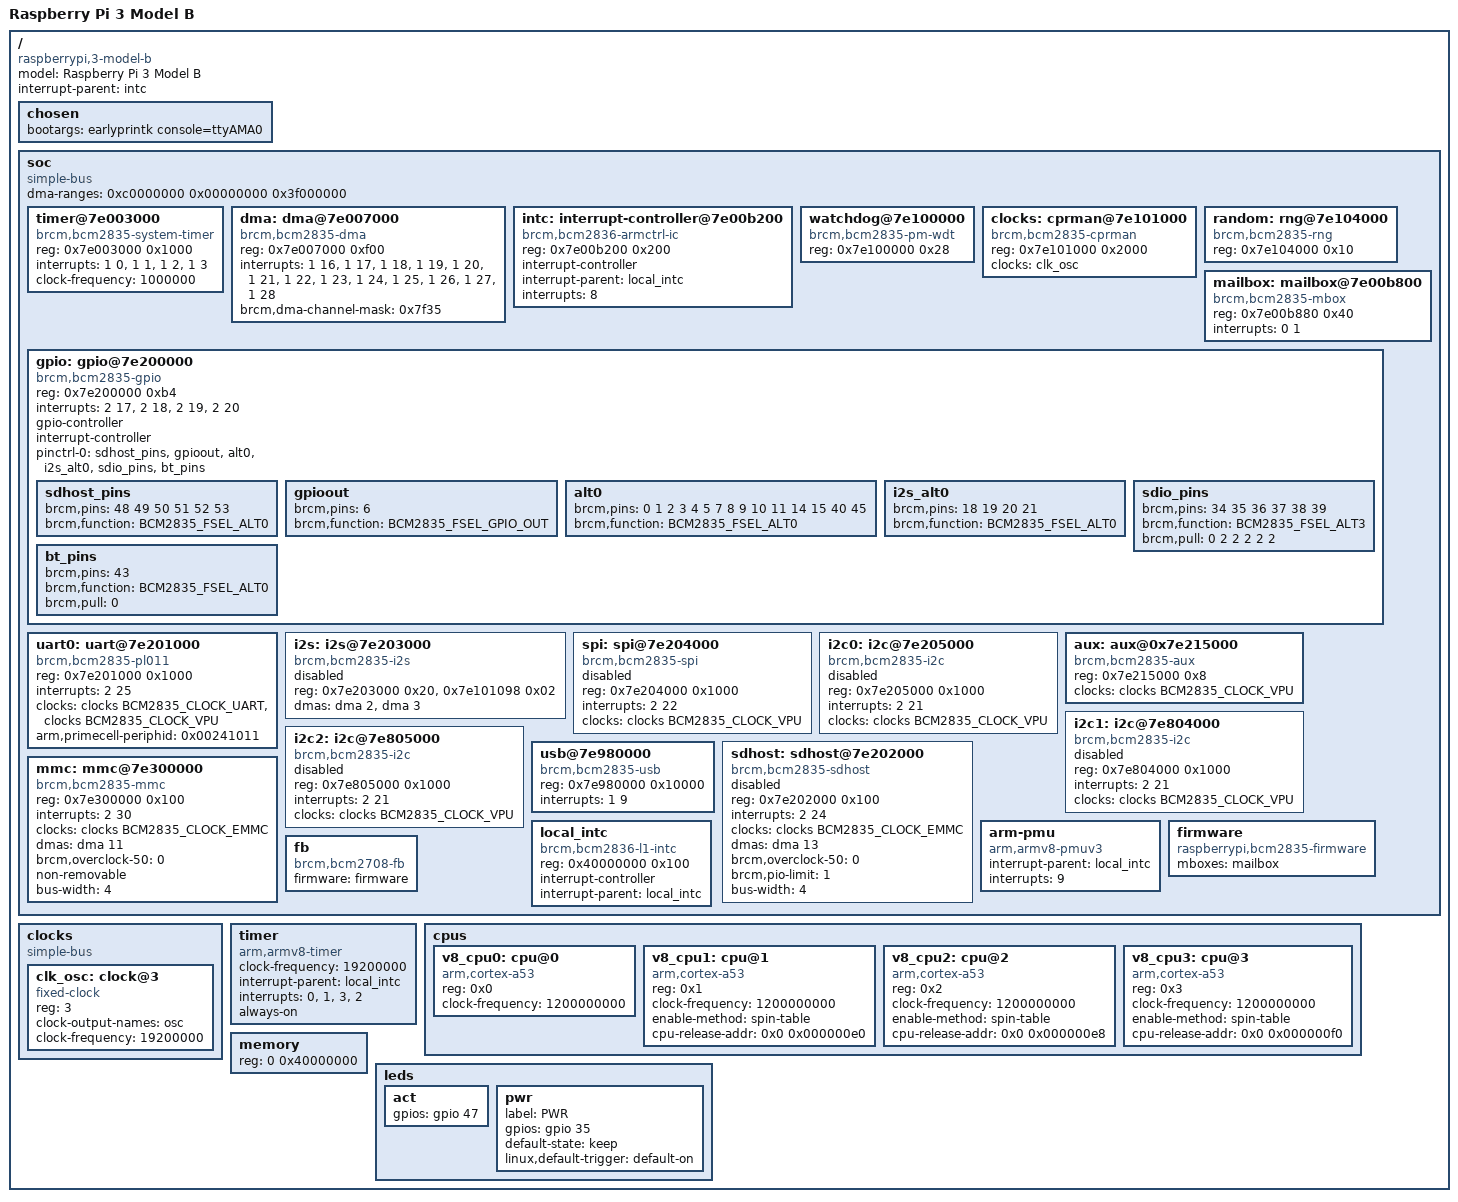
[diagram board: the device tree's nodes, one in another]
/dts-v1/;

/memreserve/ 0x00000000 0x00001000;

#include <dt-bindings/pinctrl/bcm2835.h>
#include <dt-bindings/clock/bcm2835.h>
#include "../../../../arm/boot/dts/skeleton.dtsi"

/ {
	compatible = "brcm,bcm2835";
	model = "BCM2835";
	interrupt-parent = <&intc>;

	chosen {
		bootargs = "earlyprintk console=ttyAMA0";
	};

	soc {
		compatible = "simple-bus";
		#address-cells = <1>;
		#size-cells = <1>;

		timer@7e003000 {
			compatible = "brcm,bcm2835-system-timer";
			reg = <0x7e003000 0x1000>;
			interrupts = <1 0>, <1 1>, <1 2>, <1 3>;
			/* This could be a reference to BCM2835_CLOCK_TIMER,
			 * but we don't have the driver using the common clock
			 * support yet.
			 */
			clock-frequency = <1000000>;
		};

		dma: dma@7e007000 {
			compatible = "brcm,bcm2835-dma";
			reg = <0x7e007000 0xf00>;
			interrupts = <1 16>,
				     <1 17>,
				     <1 18>,
				     <1 19>,
				     <1 20>,
				     <1 21>,
				     <1 22>,
				     <1 23>,
				     <1 24>,
				     <1 25>,
				     <1 26>,
				     <1 27>,
				     <1 28>;

			#dma-cells = <1>;
			brcm,dma-channel-mask = <0x7f35>;
		};

		intc: interrupt-controller@7e00b200 {
			compatible = "brcm,bcm2835-armctrl-ic";
			reg = <0x7e00b200 0x200>;
			interrupt-controller;
			#interrupt-cells = <2>;
		};

		watchdog@7e100000 {
			compatible = "brcm,bcm2835-pm-wdt";
			reg = <0x7e100000 0x28>;
		};

		clocks: cprman@7e101000 {
			compatible = "brcm,bcm2835-cprman";
			#clock-cells = <1>;
			reg = <0x7e101000 0x2000>;

			/* CPRMAN derives everything from the platform's
			 * oscillator.
			 */
			clocks = <&clk_osc>;
		};

		random: rng@7e104000 {
			compatible = "brcm,bcm2835-rng";
			reg = <0x7e104000 0x10>;
		};

		mailbox: mailbox@7e00b800 {
			compatible = "brcm,bcm2835-mbox";
			reg = <0x7e00b880 0x40>;
			interrupts = <0 1>;
			#mbox-cells = <0>;
		};

		gpio: gpio@7e200000 {
			compatible = "brcm,bcm2835-gpio";
			reg = <0x7e200000 0xb4>;
			/*
			 * The GPIO IP block is designed for 3 banks of GPIOs.
			 * Each bank has a GPIO interrupt for itself.
			 * There is an overall "any bank" interrupt.
			 * In order, these are GIC interrupts 17, 18, 19, 20.
			 * Since the BCM2835 only has 2 banks, the 2nd bank
			 * interrupt output appears to be mirrored onto the
			 * 3rd bank's interrupt signal.
			 * So, a bank0 interrupt shows up on 17, 20, and
			 * a bank1 interrupt shows up on 18, 19, 20!
			 */
			interrupts = <2 17>, <2 18>, <2 19>, <2 20>;

			gpio-controller;
			#gpio-cells = <2>;

			interrupt-controller;
			#interrupt-cells = <2>;
		};

		uart0: uart@7e201000 {
			compatible = "brcm,bcm2835-pl011", "arm,pl011", "arm,primecell";
			reg = <0x7e201000 0x1000>;
			interrupts = <2 25>;
			clocks = <&clocks BCM2835_CLOCK_UART>,
				 <&clocks BCM2835_CLOCK_VPU>;
			clock-names = "uartclk", "apb_pclk";
			arm,primecell-periphid = <0x00241011>;
		};

		i2s: i2s@7e203000 {
			compatible = "brcm,bcm2835-i2s";
			reg = <0x7e203000 0x20>,
			      <0x7e101098 0x02>;

			dmas = <&dma 2>,
			       <&dma 3>;
			dma-names = "tx", "rx";
			status = "disabled";
		};

		spi: spi@7e204000 {
			compatible = "brcm,bcm2835-spi";
			reg = <0x7e204000 0x1000>;
			interrupts = <2 22>;
			clocks = <&clocks BCM2835_CLOCK_VPU>;
			#address-cells = <1>;
			#size-cells = <0>;
			status = "disabled";
		};

		i2c0: i2c@7e205000 {
			compatible = "brcm,bcm2835-i2c";
			reg = <0x7e205000 0x1000>;
			interrupts = <2 21>;
			clocks = <&clocks BCM2835_CLOCK_VPU>;
			#address-cells = <1>;
			#size-cells = <0>;
			status = "disabled";
		};

		aux: aux@0x7e215000 {
			compatible = "brcm,bcm2835-aux";
			#clock-cells = <1>;
			reg = <0x7e215000 0x8>;
			clocks = <&clocks BCM2835_CLOCK_VPU>;
		};

#if 0
		sdhci: sdhci@7e300000 {
			compatible = "brcm,bcm2835-sdhci";
			reg = <0x7e300000 0x100>;
			interrupts = <2 30>;
			clocks = <&clocks BCM2835_CLOCK_EMMC>;
                        overclock_50 = <0>;
                        force_pio = <0>;
                        pio_limit = <0>;
                        debug = <0>;
			bus-width = <4>;
		};
#endif

		i2c1: i2c@7e804000 {
			compatible = "brcm,bcm2835-i2c";
			reg = <0x7e804000 0x1000>;
			interrupts = <2 21>;
			clocks = <&clocks BCM2835_CLOCK_VPU>;
			#address-cells = <1>;
			#size-cells = <0>;
			status = "disabled";
		};

		i2c2: i2c@7e805000 {
			compatible = "brcm,bcm2835-i2c";
			reg = <0x7e805000 0x1000>;
			interrupts = <2 21>;
			clocks = <&clocks BCM2835_CLOCK_VPU>;
			#address-cells = <1>;
			#size-cells = <0>;
			status = "disabled";
		};

		usb@7e980000 {
			compatible = "brcm,bcm2835-usb";
			reg = <0x7e980000 0x10000>;
			interrupts = <1 9>;
		};

		sdhost: sdhost@7e202000 {
			compatible = "brcm,bcm2835-sdhost";
			reg = <0x7e202000 0x100>;
			interrupts = <2 24>;
			clocks = <&clocks BCM2835_CLOCK_EMMC>;
			dmas = <&dma 13>;
			dma-names = "rx-tx";
			brcm,overclock-50 = <0>;
			brcm,pio-limit = <1>;
			status = "disabled";
		};

		mmc: mmc@7e300000 {
			compatible = "brcm,bcm2835-mmc";
			reg = <0x7e300000 0x100>;
			interrupts = <2 30>;
			clocks = <&clocks BCM2835_CLOCK_EMMC>;
			dmas = <&dma 11>;
			dma-names = "rx-tx";
			brcm,overclock-50 = <0>;
			status = "disabled";
		};

	};

	clocks {
		compatible = "simple-bus";
		#address-cells = <1>;
		#size-cells = <0>;


		/* The oscillator is the root of the clock tree. */
		clk_osc: clock@3 {
			compatible = "fixed-clock";
			reg = <3>;
			#clock-cells = <0>;
			clock-output-names = "osc";
			clock-frequency = <19200000>;
		};

	};
};

/ {
	compatible = "brcm,bcm2837";

	soc {
		ranges = <0x7e000000 0x3f000000 0x1000000>,
			 <0x40000000 0x40000000 0x00001000>;
		dma-ranges = <0xc0000000 0x00000000 0x3f000000>;

		local_intc: local_intc {
			compatible = "brcm,bcm2836-l1-intc";
			reg = <0x40000000 0x100>;
			interrupt-controller;
			#interrupt-cells = <1>;
			interrupt-parent = <&local_intc>;
		};

		arm-pmu {
			compatible = "arm,armv8-pmuv3";
			interrupt-parent = <&local_intc>;
			interrupts = <9>;
		};

		firmware: firmware {
			compatible = "raspberrypi,bcm2835-firmware";
			mboxes = <&mailbox>;
		};

		fb: fb {
			compatible = "brcm,bcm2708-fb";
			firmware = <&firmware>;
			status = "okay";
		};

	};

	timer {
		compatible = "arm,armv8-timer";
		clock-frequency = <19200000>;
		interrupt-parent = <&local_intc>;
		interrupts = <0>, // PHYS_SECURE_PPI
			     <1>, // PHYS_NONSECURE_PPI
			     <3>, // VIRT_PPI
			     <2>; // HYP_PPI
		always-on;
	};


	cpus: cpus {
		#address-cells = <1>;
		#size-cells = <0>;

		v8_cpu0: cpu@0 {
			device_type = "cpu";
			compatible = "arm,cortex-a53", "arm,armv8";
			reg = <0x0>;
			clock-frequency = <1200000000>;
		};

		v8_cpu1: cpu@1 {
			device_type = "cpu";
			compatible = "arm,cortex-a53", "arm,armv8";
			reg = <0x1>;
			clock-frequency = <1200000000>;
			enable-method = "spin-table";
			cpu-release-addr = <0x0 0x000000e0>;
		};

		v8_cpu2: cpu@2 {
			device_type = "cpu";
			compatible = "arm,cortex-a53", "arm,armv8";
			reg = <0x2>;
			clock-frequency = <1200000000>;
                        enable-method = "spin-table";
			cpu-release-addr = <0x0 0x000000e8>;
		};

		v8_cpu3: cpu@3 {
			device_type = "cpu";
			compatible = "arm,cortex-a53", "arm,armv8";
			reg = <0x3>;
			clock-frequency = <1200000000>;
                        enable-method = "spin-table";
			cpu-release-addr = <0x0 0x000000f0>;
		};
	};
};

/* Make the BCM2835-style global interrupt controller be a child of the
 * CPU-local interrupt controller.
 */
&intc {
	compatible = "brcm,bcm2836-armctrl-ic";
	reg = <0x7e00b200 0x200>;
	interrupt-parent = <&local_intc>;
	interrupts = <8>;
};

/ {
	compatible = "raspberrypi,3-model-b", "brcm,bcm2837", "brcm,bcm2708";
	model = "Raspberry Pi 3 Model B";

	memory {
		reg = <0 0x40000000>;
	};

	leds {
		act {
			gpios = <&gpio 47 0>;
		};

		pwr {
			label = "PWR";
			gpios = <&gpio 35 0>;
			default-state = "keep";
			linux,default-trigger = "default-on";
		};
	};
};

&gpio {
	pinctrl-0 = <&sdhost_pins &gpioout &alt0 &i2s_alt0 &sdio_pins &bt_pins>;

	sdhost_pins: sdhost_pins {
		brcm,pins = <48 49 50 51 52 53>;
		brcm,function = <BCM2835_FSEL_ALT0>; /* alt0 */
	};

	gpioout: gpioout {
		brcm,pins = <6>;
		brcm,function = <BCM2835_FSEL_GPIO_OUT>;
	};

	alt0: alt0 {
		brcm,pins = <0 1 2 3 4 5 7 8 9 10 11 14 15 40 45>;
		brcm,function = <BCM2835_FSEL_ALT0>;
	};

	/* I2S interface */
	i2s_alt0: i2s_alt0 {
		brcm,pins = <18 19 20 21>;
		brcm,function = <BCM2835_FSEL_ALT0>;
	};

#if 0
	alt3: alt3 {
		brcm,pins = <48 49 50 51 52 53>;
		brcm,function = <BCM2835_FSEL_ALT3>;
	};
#endif

	sdio_pins: sdio_pins {
		brcm,pins =     <34 35 36 37 38 39>;
		brcm,function = <BCM2835_FSEL_ALT3>; 
		brcm,pull =     <0 2 2 2 2 2>;
	};


	bt_pins: bt_pins {
		brcm,pins = <43>;
		brcm,function = <BCM2835_FSEL_ALT0>; /* alt0:GPCLK2 */
		brcm,pull = <0>;
	};
};

&sdhost {
	bus-width = <4>;
};

&mmc {
	non-removable;
	bus-width = <4>;
	brcm,overclock-50 = <0>;
	status = "okay";
};


/ {
	__overrides__ {
		sd_overclock = <&sdhost>,"brcm,overclock-50:0";
		sd_force_pio = <&sdhost>,"brcm,force-pio?";
		sd_pio_limit = <&sdhost>,"brcm,pio-limit:0";
		sd_debug     = <&sdhost>,"brcm,debug";
	};
};
